# FM33FK5XX register map
File version: 1.0
CPU: Cortex-M33 r1p0, little endian, MPU, FPU, 3 interrupt priority bits
Registers are 32-bit, read-write, reset 0x0 unless marked. A register's access mark holds for its fields unless they carry their own. Offsets are from the block's base; [hi:lo] are bit positions; {n}, {i} and the like mark numbered series.

## EPWM0 — EPWM0 module information
Base 0x40011000
Same registers: EPWM1 0x40011100, EPWM2 0x40011200, EPWM3 0x40011300
0x00 PRD
  [15:0] PRD — PRD field description
0x04 PHSR
  [15:0] PHS — PHS field description
0x08 PSC
  [15:0] PSC — PSC field description
0x0C CNTR
  [15:0] CNT — CNT field description
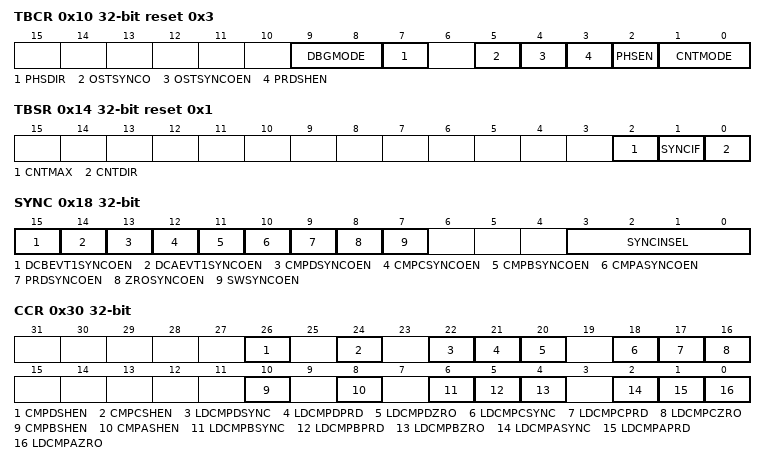
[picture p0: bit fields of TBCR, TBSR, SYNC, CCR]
0x10 TBCR reset 0x3
  [9:8] DBGMODE — DBGMODE field description
  [7] PHSDIR — PHSDIR field description
  [5] OSTSYNCO — OSTSYNCO field description
  [4] OSTSYNCOEN — OSTSYNCOEN field description
  [3] PRDSHEN — PRDSHEN field description
  [2] PHSEN — PHSEN field description
  [1:0] CNTMODE — CNTMODE field description
0x14 TBSR access per field reset 0x1
  [2] CNTMAX rw — CNTMAX field description
  [1] SYNCIF rw — SYNCIF field description
  [0] CNTDIR ro — CNTDIR field description
0x18 SYNC
  [15] DCBEVT1SYNCOEN — DCBEVT1SYNCOEN field description
  [14] DCAEVT1SYNCOEN — DCAEVT1SYNCOEN field description
  [13] CMPDSYNCOEN — CMPDSYNCOEN field description
  [12] CMPCSYNCOEN — CMPCSYNCOEN field description
  [11] CMPBSYNCOEN — CMPBSYNCOEN field description
  [10] CMPASYNCOEN — CMPASYNCOEN field description
  [9] PRDSYNCOEN — PRDSYNCOEN field description
  [8] ZROSYNCOEN — ZROSYNCOEN field description
  [7] SWSYNCOEN — SWSYNCOEN field description
  [3:0] SYNCINSEL — SYNCINSEL field description
0x1C SWACT wo
  [0] SWSYNC — SWSYNC field description
0x20 CMPA
  [15:0] CMPA — CMPA field description
0x24 CMPB
  [15:0] CMPB — CMPB field description
0x28 CMPC
  [15:0] CMPC — CMPC field description
0x2C CMPD
  [15:0] CMPD — CMPD field description
0x30 CCR
  [26] CMPDSHEN — CMPDSHEN field description
  [24] CMPCSHEN — CMPCSHEN field description
  [22] LDCMPDSYNC — LDCMPDSYNC field description
  [21] LDCMPDPRD — LDCMPDPRD field description
  [20] LDCMPDZRO — LDCMPDZRO field description
  [18] LDCMPCSYNC — LDCMPCSYNC field description
  [17] LDCMPCPRD — LDCMPCPRD field description
  [16] LDCMPCZRO — LDCMPCZRO field description
  [10] CMPBSHEN — CMPBSHEN field description
  [8] CMPASHEN — CMPASHEN field description
  [6] LDCMPBSYNC — LDCMPBSYNC field description
  [5] LDCMPBPRD — LDCMPBPRD field description
  [4] LDCMPBZRO — LDCMPBZRO field description
  [2] LDCMPASYNC — LDCMPASYNC field description
  [1] LDCMPAPRD — LDCMPAPRD field description
  [0] LDCMPAZRO — LDCMPAZRO field description
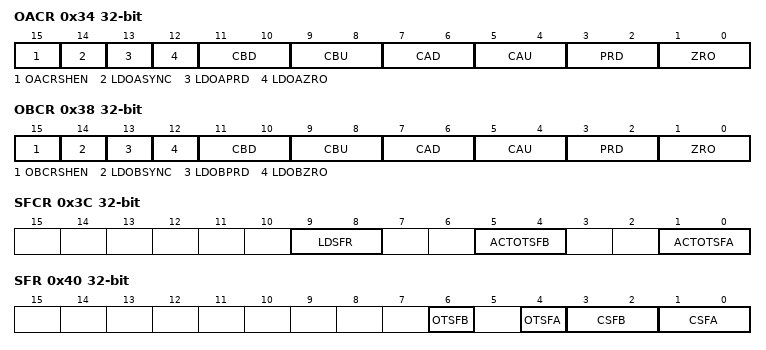
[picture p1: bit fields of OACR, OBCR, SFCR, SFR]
0x34 OACR
  [15] OACRSHEN — OACRSHEN field description
  [14] LDOASYNC — LDOASYNC field description
  [13] LDOAPRD — LDOAPRD field description
  [12] LDOAZRO — LDOAZRO field description
  [11:10] CBD — CBD field description
  [9:8] CBU — CBU field description
  [7:6] CAD — CAD field description
  [5:4] CAU — CAU field description
  [3:2] PRD — PRD field description
  [1:0] ZRO — ZRO field description
0x38 OBCR
  [15] OBCRSHEN — OBCRSHEN field description
  [14] LDOBSYNC — LDOBSYNC field description
  [13] LDOBPRD — LDOBPRD field description
  [12] LDOBZRO — LDOBZRO field description
  [11:10] CBD — CBD field description
  [9:8] CBU — CBU field description
  [7:6] CAD — CAD field description
  [5:4] CAU — CAU field description
  [3:2] PRD — PRD field description
  [1:0] ZRO — ZRO field description
0x3C SFCR
  [9:8] LDSFR — LDSFR field description
  [5:4] ACTOTSFB — ACTOTSFB field description
  [1:0] ACTOTSFA — ACTOTSFA field description
0x40 SFR
  [6] OTSFB — OTSFB field description
  [4] OTSFA — OTSFA field description
  [3:2] CSFB — CSFB field description
  [1:0] CSFA — CSFA field description
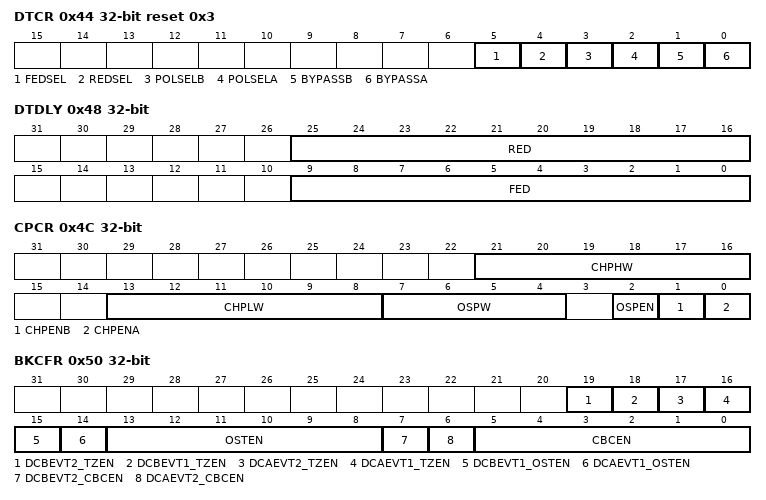
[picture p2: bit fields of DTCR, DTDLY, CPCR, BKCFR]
0x44 DTCR reset 0x3
  [5] FEDSEL — FEDSEL field description
  [4] REDSEL — REDSEL field description
  [3] POLSELB — POLSELB field description
  [2] POLSELA — POLSELA field description
  [1] BYPASSB — BYPASSB field description
  [0] BYPASSA — BYPASSA field description
0x48 DTDLY
  [25:16] RED — RED field description
  [9:0] FED — FED field description
0x4C CPCR
  [21:16] CHPHW — CHPHW field description
  [13:8] CHPLW — CHPLW field description
  [7:4] OSPW — OSPW field description
  [2] OSPEN — OSPEN field description
  [1] CHPENB — CHPENB field description
  [0] CHPENA — CHPENA field description
0x50 BKCFR
  [19] DCBEVT2_TZEN — DCBEVT2_TZEN field description
  [18] DCBEVT1_TZEN — DCBEVT1_TZEN field description
  [17] DCAEVT2_TZEN — DCAEVT2_TZEN field description
  [16] DCAEVT1_TZEN — DCAEVT1_TZEN field description
  [15] DCBEVT1_OSTEN — DCBEVT1_OSTEN field description
  [14] DCAEVT1_OSTEN — DCAEVT1_OSTEN field description
  [13:8] OSTEN — OSTEN field description
  [7] DCBEVT2_CBCEN — DCBEVT2_CBCEN field description
  [6] DCAEVT2_CBCEN — DCAEVT2_CBCEN field description
  [5:0] CBCEN — CBCEN field description
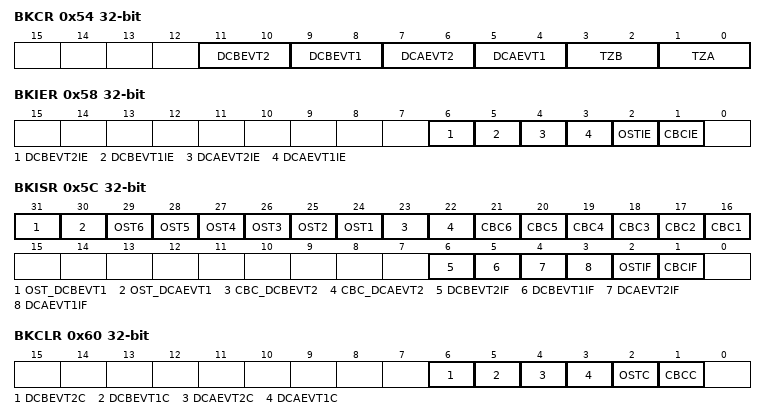
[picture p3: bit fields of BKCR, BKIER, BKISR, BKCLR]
0x54 BKCR
  [11:10] DCBEVT2 — DCBEVT2 field description
  [9:8] DCBEVT1 — DCBEVT1 field description
  [7:6] DCAEVT2 — DCAEVT2 field description
  [5:4] DCAEVT1 — DCAEVT1 field description
  [3:2] TZB — TZB field description
  [1:0] TZA — TZA field description
0x58 BKIER
  [6] DCBEVT2IE — DCBEVT2IE field description
  [5] DCBEVT1IE — DCBEVT1IE field description
  [4] DCAEVT2IE — DCAEVT2IE field description
  [3] DCAEVT1IE — DCAEVT1IE field description
  [2] OSTIE — OSTIE field description
  [1] CBCIE — CBCIE field description
0x5C BKISR access per field
  [31] OST_DCBEVT1 ro — OST_DCBEVT1 field description
  [30] OST_DCAEVT1 ro — OST_DCAEVT1 field description
  [n+23] OST{n} ro (n=1..6) — OST{n} field description
  [23] CBC_DCBEVT2 ro — CBC_DCBEVT2 field description
  [22] CBC_DCAEVT2 ro — CBC_DCAEVT2 field description
  [n+15] CBC{n} ro (n=1..6) — CBC{n} field description
  [6] DCBEVT2IF rw — DCBEVT2IF field description
  [5] DCBEVT1IF rw — DCBEVT1IF field description
  [4] DCAEVT2IF rw — DCAEVT2IF field description
  [3] DCAEVT1IF rw — DCAEVT1IF field description
  [2] OSTIF rw — OSTIF field description
  [1] CBCIF rw — CBCIF field description
0x60 BKCLR
  [6] DCBEVT2C — DCBEVT2C field description
  [5] DCBEVT1C — DCBEVT1C field description
  [4] DCAEVT2C — DCAEVT2C field description
  [3] DCAEVT1C — DCAEVT1C field description
  [2] OSTC — OSTC field description
  [1] CBCC — CBCC field description
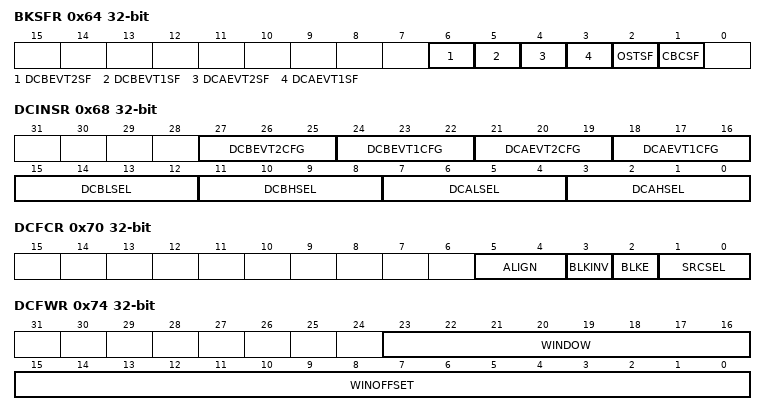
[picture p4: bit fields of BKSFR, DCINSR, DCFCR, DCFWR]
0x64 BKSFR
  [6] DCBEVT2SF — DCBEVT2SF field description
  [5] DCBEVT1SF — DCBEVT1SF field description
  [4] DCAEVT2SF — DCAEVT2SF field description
  [3] DCAEVT1SF — DCAEVT1SF field description
  [2] OSTSF — OSTSF field description
  [1] CBCSF — CBCSF field description
0x68 DCINSR
  [27:25] DCBEVT2CFG — DCBEVT2CFG field description
  [24:22] DCBEVT1CFG — DCBEVT1CFG field description
  [21:19] DCAEVT2CFG — DCAEVT2CFG field description
  [18:16] DCAEVT1CFG — DCAEVT1CFG field description
  [15:12] DCBLSEL — DCBLSEL field description
  [11:8] DCBHSEL — DCBHSEL field description
  [7:4] DCALSEL — DCALSEL field description
  [3:0] DCAHSEL — DCAHSEL field description
0x70 DCFCR
  [5:4] ALIGN — ALIGN field description
  [3] BLKINV — BLKINV field description
  [2] BLKE — BLKE field description
  [1:0] SRCSEL — SRCSEL field description
0x74 DCFWR
  [23:16] WINDOW — WINDOW field description
  [15:0] WINOFFSET — WINOFFSET field description
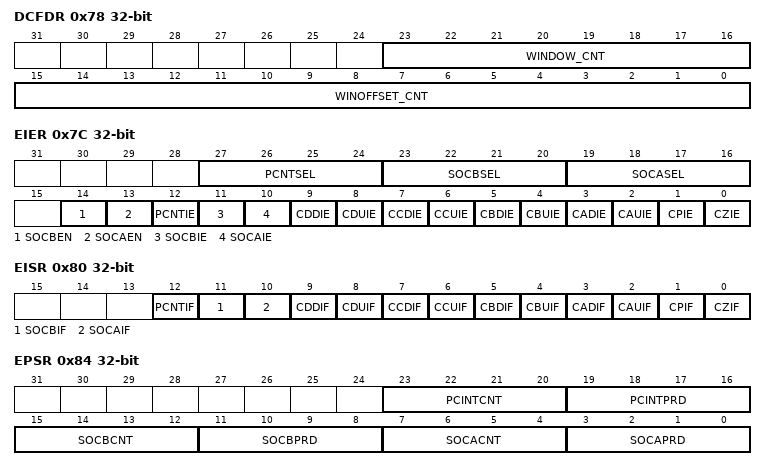
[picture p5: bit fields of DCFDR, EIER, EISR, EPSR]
0x78 DCFDR ro
  [23:16] WINDOW_CNT — WINDOW_CNT field description
  [15:0] WINOFFSET_CNT — WINOFFSET_CNT field description
0x7C EIER
  [27:24] PCNTSEL — PCNTSEL field description
  [23:20] SOCBSEL — SOCBSEL field description
  [19:16] SOCASEL — SOCASEL field description
  [14] SOCBEN — SOCBEN field description
  [13] SOCAEN — SOCAEN field description
  [12] PCNTIE — PCNTIE field description
  [11] SOCBIE — SOCBIE field description
  [10] SOCAIE — SOCAIE field description
  [9] CDDIE — CDDIE field description
  [8] CDUIE — CDUIE field description
  [7] CCDIE — CCDIE field description
  [6] CCUIE — CCUIE field description
  [5] CBDIE — CBDIE field description
  [4] CBUIE — CBUIE field description
  [3] CADIE — CADIE field description
  [2] CAUIE — CAUIE field description
  [1] CPIE — CPIE field description
  [0] CZIE — CZIE field description
0x80 EISR
  [12] PCNTIF — PCNTIF field description
  [11] SOCBIF — SOCBIF field description
  [10] SOCAIF — SOCAIF field description
  [9] CDDIF — CDDIF field description
  [8] CDUIF — CDUIF field description
  [7] CCDIF — CCDIF field description
  [6] CCUIF — CCUIF field description
  [5] CBDIF — CBDIF field description
  [4] CBUIF — CBUIF field description
  [3] CADIF — CADIF field description
  [2] CAUIF — CAUIF field description
  [1] CPIF — CPIF field description
  [0] CZIF — CZIF field description
0x84 EPSR access per field
  [23:20] PCINTCNT ro — PCINTCNT field description
  [19:16] PCINTPRD rw — PCINTPRD field description
  [15:12] SOCBCNT ro — SOCBCNT field description
  [11:8] SOCBPRD rw — SOCBPRD field description
  [7:4] SOCACNT ro — SOCACNT field description
  [3:0] SOCAPRD rw — SOCAPRD field description
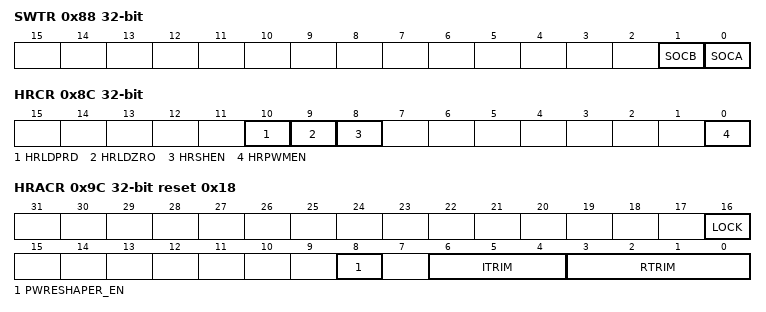
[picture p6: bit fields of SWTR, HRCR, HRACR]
0x88 SWTR wo
  [1] SOCB — SOCB field description
  [0] SOCA — SOCA field description
0x8C HRCR
  [10] HRLDPRD — HRLDPRD field description
  [9] HRLDZRO — HRLDZRO field description
  [8] HRSHEN — HRSHEN field description
  [0] HRPWMEN — HRPWMEN field description
0x90 HRPRD
  [4:0] HRPRD — HRPRD field description
0x94 HRCMPA
  [4:0] HRCMPA — HRCMPA field description
0x98 HRCMPB
  [4:0] HRCMPB — HRCMPB field description
0x9C HRACR access per field reset 0x18
  [16] LOCK ro — LOCK field description
  [8] PWRESHAPER_EN rw — PWRESHAPER_EN field description
  [6:4] ITRIM rw — ITRIM field description
  [3:0] RTRIM rw — RTRIM field description
0xF8 LINK
  [2:0] LINK — LINK field description
0xFC CR
  [0] START — START field description
